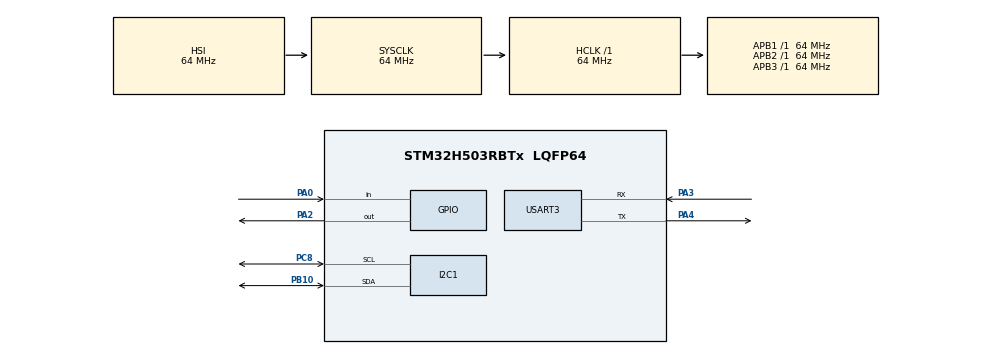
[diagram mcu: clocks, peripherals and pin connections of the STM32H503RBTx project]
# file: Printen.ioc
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BOOTPATH.BootPathName=LEGACY
BOOTPATH.UserSelectedBootPath=LEGACY
I2C1.Timing=0x10707DBC
Mcu.Family=STM32H5
Mcu.Name=STM32H503RBTx
Mcu.Package=LQFP64
NVIC.PriorityGroup=NVIC_PRIORITYGROUP_4
NVIC.TIM3_IRQn=true\:0\:0\:false\:false\:true\:true\:true\:true
PA0.Signal=GPIO_Input
PA13(JTMS/SWDIO).Mode=Serial_Wire
PA13(JTMS/SWDIO).Signal=DEBUG_JTMS-SWDIO
PA14(JTCK/SWCLK).Mode=Serial_Wire
PA14(JTCK/SWCLK).Signal=DEBUG_JTCK-SWCLK
PA2.Signal=GPIO_Output
PA3.Mode=Asynchronous
PA3.Signal=USART3_RX
PA4.Mode=Asynchronous
PA4.Signal=USART3_TX
PB10.Mode=I2C
PB10.Signal=I2C1_SDA
PC8.Mode=I2C
PC8.Signal=I2C1_SCL
ProjectManager.HeapSize=0x200
ProjectManager.StackSize=0x400
ProjectManager.TargetToolchain=STM32CubeIDE
RCC.ADCFreq_Value=64000000
RCC.AHBFreq_Value=64000000
RCC.APB1Freq_Value=64000000
RCC.APB1TimFreq_Value=64000000
RCC.APB2Freq_Value=64000000
RCC.APB2TimFreq_Value=64000000
RCC.APB3Freq_Value=64000000
RCC.CSI_VALUE=4000000
RCC.CortexFreq_Value=64000000
RCC.EPOD_VALUE=4000000
RCC.HCLKFreq_Value=64000000
RCC.HSE_VALUE=24000000
RCC.HSI48_VALUE=48000000
RCC.HSIDiv=RCC_HSI_DIV1
RCC.HSI_VALUE=64000000
RCC.LSE_VALUE=32768
RCC.LSIRC_VALUE=32000
RCC.PLLN=32
RCC.SYSCLKFreq_VALUE=64000000
RCC.USBFreq_Value=48000000
RCC.VCOOutputFreq_Value=128000000
TIM3.Prescaler=64-1
USART3.VirtualMode-Asynchronous=VM_ASYNC
VP_BOOTPATH_VS_BOOTPATH.Mode=BP_Activate
VP_CORTEX_M33_NS_VS_Hclk.Mode=Hclk_Mode
VP_MEMORYMAP_VS_MEMORYMAP.Mode=CurAppReg
VP_PWR_VS_DBSignals.Mode=DisableDeadBatterySignals
VP_PWR_VS_LPOM.Mode=PowerOptimisation
VP_PWR_VS_SECSignals.Mode=Security/Privilege
VP_TIM3_VS_ClockSourceINT.Mode=Internal
board=NUCLEO-H503RB

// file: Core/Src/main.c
/* USER CODE BEGIN Header */
/**
  ******************************************************************************
  * @file           : main.c
  * @brief          : Main program body
  ******************************************************************************
  * @attention
  *
  * Copyright (c) 2024 STMicroelectronics.
  * All rights reserved.
  *
  * This software is licensed under terms that can be found in the LICENSE file
  * in the root directory of this software component.
  * If no LICENSE file comes with this software, it is provided AS-IS.
  *
  ******************************************************************************
  */
/* USER CODE END Header */
#include "main.h"
#include "main_loop.hpp"

/* USER CODE BEGIN PTD */
#define usTIM TIM3
/* USER CODE END PTD */

I2C_HandleTypeDef hi2c1;

TIM_HandleTypeDef htim3;

UART_HandleTypeDef huart3;

void SystemClock_Config(void);
static void MX_GPIO_Init(void);
static void MX_USART3_UART_Init(void);
static void MX_TIM3_Init(void);
static void MX_I2C1_Init(void);
/* USER CODE BEGIN PFP */
void usDelay(uint32_t uSec);
/* USER CODE END PFP */

int main(void)
{

  /* MCU Configuration--------------------------------------------------------*/

  /* Reset of all peripherals, Initializes the Flash interface and the Systick. */
  HAL_Init();

  /* Configure the system clock */
  SystemClock_Config();

  /* Initialize all configured peripherals */
  MX_GPIO_Init();
  MX_USART3_UART_Init();
  MX_TIM3_Init();
  MX_I2C1_Init();

  /* Infinite loop */
  while (1)
  {
	  main_loop_c();
  }
}

void SystemClock_Config(void)
{
  RCC_OscInitTypeDef RCC_OscInitStruct = {0};
  RCC_ClkInitTypeDef RCC_ClkInitStruct = {0};

  /** Configure the main internal regulator output voltage
  */
  __HAL_PWR_VOLTAGESCALING_CONFIG(PWR_REGULATOR_VOLTAGE_SCALE3);

  while(!__HAL_PWR_GET_FLAG(PWR_FLAG_VOSRDY)) {}

  /** Initializes the RCC Oscillators according to the specified parameters
  * in the RCC_OscInitTypeDef structure.
  */
  RCC_OscInitStruct.OscillatorType = RCC_OSCILLATORTYPE_HSI;
  RCC_OscInitStruct.HSIState = RCC_HSI_ON;
  RCC_OscInitStruct.HSIDiv = RCC_HSI_DIV1;
  RCC_OscInitStruct.HSICalibrationValue = RCC_HSICALIBRATION_DEFAULT;
  RCC_OscInitStruct.PLL.PLLState = RCC_PLL_NONE;
  if (HAL_RCC_OscConfig(&RCC_OscInitStruct) != HAL_OK)
  {
    Error_Handler();
  }

  /** Initializes the CPU, AHB and APB buses clocks
  */
  RCC_ClkInitStruct.ClockType = RCC_CLOCKTYPE_HCLK|RCC_CLOCKTYPE_SYSCLK
                              |RCC_CLOCKTYPE_PCLK1|RCC_CLOCKTYPE_PCLK2
                              |RCC_CLOCKTYPE_PCLK3;
  RCC_ClkInitStruct.SYSCLKSource = RCC_SYSCLKSOURCE_HSI;
  RCC_ClkInitStruct.AHBCLKDivider = RCC_SYSCLK_DIV1;
  RCC_ClkInitStruct.APB1CLKDivider = RCC_HCLK_DIV1;
  RCC_ClkInitStruct.APB2CLKDivider = RCC_HCLK_DIV1;
  RCC_ClkInitStruct.APB3CLKDivider = RCC_HCLK_DIV1;

  if (HAL_RCC_ClockConfig(&RCC_ClkInitStruct, FLASH_LATENCY_3) != HAL_OK)
  {
    Error_Handler();
  }

  /** Configure the programming delay
  */
  __HAL_FLASH_SET_PROGRAM_DELAY(FLASH_PROGRAMMING_DELAY_1);
}

static void MX_I2C1_Init(void)
{

  hi2c1.Instance = I2C1;
  hi2c1.Init.Timing = 0x10707DBC;
  hi2c1.Init.OwnAddress1 = 0;
  hi2c1.Init.AddressingMode = I2C_ADDRESSINGMODE_7BIT;
  hi2c1.Init.DualAddressMode = I2C_DUALADDRESS_DISABLE;
  hi2c1.Init.OwnAddress2 = 0;
  hi2c1.Init.OwnAddress2Masks = I2C_OA2_NOMASK;
  hi2c1.Init.GeneralCallMode = I2C_GENERALCALL_DISABLE;
  hi2c1.Init.NoStretchMode = I2C_NOSTRETCH_DISABLE;
  if (HAL_I2C_Init(&hi2c1) != HAL_OK)
  {
    Error_Handler();
  }

  /** Configure Analogue filter
  */
  if (HAL_I2CEx_ConfigAnalogFilter(&hi2c1, I2C_ANALOGFILTER_ENABLE) != HAL_OK)
  {
    Error_Handler();
  }

  /** Configure Digital filter
  */
  if (HAL_I2CEx_ConfigDigitalFilter(&hi2c1, 0) != HAL_OK)
  {
    Error_Handler();
  }

}

static void MX_TIM3_Init(void)
{

  TIM_ClockConfigTypeDef sClockSourceConfig = {0};
  TIM_MasterConfigTypeDef sMasterConfig = {0};

  htim3.Instance = TIM3;
  htim3.Init.Prescaler = 64-1;
  htim3.Init.CounterMode = TIM_COUNTERMODE_UP;
  htim3.Init.Period = 65535;
  htim3.Init.ClockDivision = TIM_CLOCKDIVISION_DIV1;
  htim3.Init.AutoReloadPreload = TIM_AUTORELOAD_PRELOAD_DISABLE;
  if (HAL_TIM_Base_Init(&htim3) != HAL_OK)
  {
    Error_Handler();
  }
  sClockSourceConfig.ClockSource = TIM_CLOCKSOURCE_INTERNAL;
  if (HAL_TIM_ConfigClockSource(&htim3, &sClockSourceConfig) != HAL_OK)
  {
    Error_Handler();
  }
  sMasterConfig.MasterOutputTrigger = TIM_TRGO_RESET;
  sMasterConfig.MasterSlaveMode = TIM_MASTERSLAVEMODE_DISABLE;
  if (HAL_TIMEx_MasterConfigSynchronization(&htim3, &sMasterConfig) != HAL_OK)
  {
    Error_Handler();
  }

}

static void MX_USART3_UART_Init(void)
{

  huart3.Instance = USART3;
  huart3.Init.BaudRate = 115200;
  huart3.Init.WordLength = UART_WORDLENGTH_8B;
  huart3.Init.StopBits = UART_STOPBITS_1;
  huart3.Init.Parity = UART_PARITY_NONE;
  huart3.Init.Mode = UART_MODE_TX_RX;
  huart3.Init.HwFlowCtl = UART_HWCONTROL_NONE;
  huart3.Init.OverSampling = UART_OVERSAMPLING_16;
  huart3.Init.OneBitSampling = UART_ONE_BIT_SAMPLE_DISABLE;
  huart3.Init.ClockPrescaler = UART_PRESCALER_DIV1;
  huart3.AdvancedInit.AdvFeatureInit = UART_ADVFEATURE_NO_INIT;
  if (HAL_UART_Init(&huart3) != HAL_OK)
  {
    Error_Handler();
  }
  if (HAL_UARTEx_SetTxFifoThreshold(&huart3, UART_TXFIFO_THRESHOLD_1_8) != HAL_OK)
  {
    Error_Handler();
  }
  if (HAL_UARTEx_SetRxFifoThreshold(&huart3, UART_RXFIFO_THRESHOLD_1_8) != HAL_OK)
  {
    Error_Handler();
  }
  if (HAL_UARTEx_DisableFifoMode(&huart3) != HAL_OK)
  {
    Error_Handler();
  }

}

static void MX_GPIO_Init(void)
{
  GPIO_InitTypeDef GPIO_InitStruct = {0};

  /* GPIO Ports Clock Enable */
  __HAL_RCC_GPIOA_CLK_ENABLE();
  __HAL_RCC_GPIOB_CLK_ENABLE();
  __HAL_RCC_GPIOC_CLK_ENABLE();

  /*Configure GPIO pin Output Level */
  HAL_GPIO_WritePin(GPIOA, GPIO_PIN_2, GPIO_PIN_RESET);

  /*Configure GPIO pin : PA0 */
  GPIO_InitStruct.Pin = GPIO_PIN_0;
  GPIO_InitStruct.Mode = GPIO_MODE_INPUT;
  GPIO_InitStruct.Pull = GPIO_NOPULL;
  HAL_GPIO_Init(GPIOA, &GPIO_InitStruct);

  /*Configure GPIO pin : PA2 */
  GPIO_InitStruct.Pin = GPIO_PIN_2;
  GPIO_InitStruct.Mode = GPIO_MODE_OUTPUT_PP;
  GPIO_InitStruct.Pull = GPIO_NOPULL;
  GPIO_InitStruct.Speed = GPIO_SPEED_FREQ_LOW;
  HAL_GPIO_Init(GPIOA, &GPIO_InitStruct);

}

/* USER CODE BEGIN 4 */
void usDelay(uint32_t uSec) {

	if (uSec < 2) uSec = 2;
	usTIM->ARR = uSec - 1;
	usTIM->EGR = 1;
	usTIM->SR &= ~1;
	usTIM->CR1 |= 1;
	while((usTIM->SR&0x0001) != 1);
	usTIM->SR &= ~(0x0001);

}
/* USER CODE END 4 */

void Error_Handler(void)
{
  /* USER CODE BEGIN Error_Handler_Debug */
  /* User can add his own implementation to report the HAL error return state */
  __disable_irq();

  while (1)
  {
	  main_loop_c();
	  HAL_Delay(1000);  // Wait for 1 second between measurements
  }
  /* USER CODE END Error_Handler_Debug */
}
